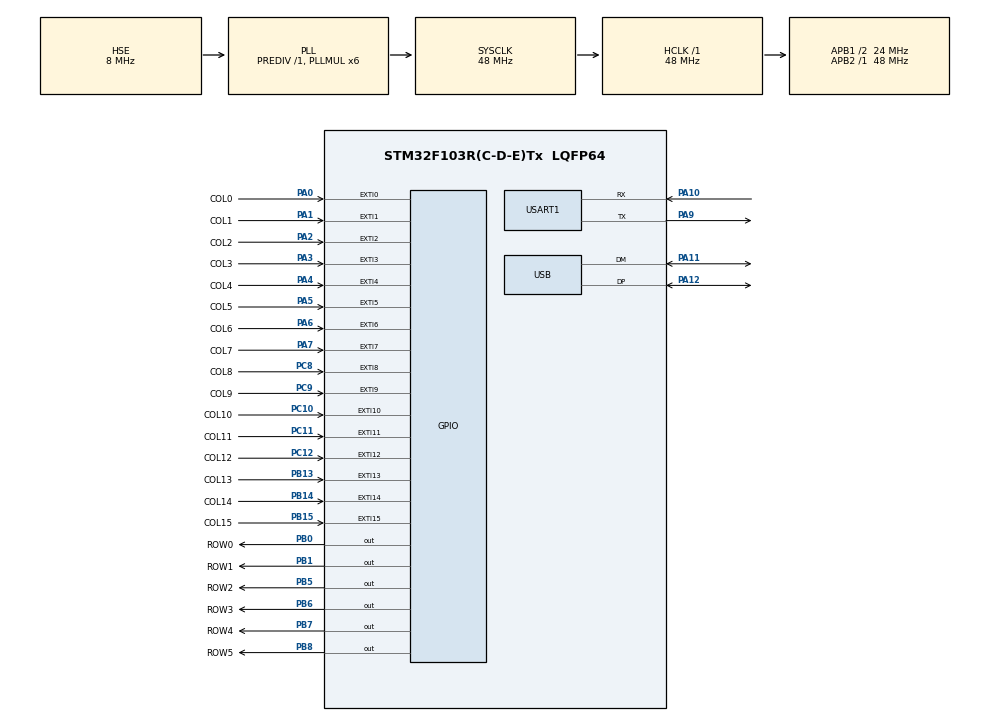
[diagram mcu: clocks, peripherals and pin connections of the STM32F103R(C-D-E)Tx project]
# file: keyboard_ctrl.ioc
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Mcu.Family=STM32F1
Mcu.Name=STM32F103R(C-D-E)Tx
Mcu.Package=LQFP64
NVIC.EXTI0_IRQn=true\:3\:0\:true\:false\:true\:true\:true\:true
NVIC.EXTI15_10_IRQn=true\:3\:0\:true\:false\:true\:true\:true\:true
NVIC.EXTI1_IRQn=true\:3\:0\:true\:false\:true\:true\:true\:true
NVIC.EXTI2_IRQn=true\:3\:0\:true\:false\:true\:true\:true\:true
NVIC.EXTI3_IRQn=true\:3\:0\:true\:false\:true\:true\:true\:true
NVIC.EXTI4_IRQn=true\:3\:0\:true\:false\:true\:true\:true\:true
NVIC.EXTI9_5_IRQn=true\:0\:0\:false\:false\:true\:true\:true\:true
NVIC.PriorityGroup=NVIC_PRIORITYGROUP_4
NVIC.TIM4_IRQn=true\:2\:0\:true\:false\:true\:true\:true\:true
NVIC.USART1_IRQn=true\:1\:0\:true\:false\:true\:true\:true\:true
NVIC.USB_LP_CAN1_RX0_IRQn=true\:0\:0\:false\:false\:true\:false\:true\:true
PA0-WKUP.GPIO_Label=COL0
PA0-WKUP.GPIO_ModeDefaultEXTI=GPIO_MODE_IT_FALLING
PA0-WKUP.GPIO_PuPd=GPIO_PULLUP
PA0-WKUP.Signal=GPXTI0
PA1.GPIO_Label=COL1
PA1.GPIO_ModeDefaultEXTI=GPIO_MODE_IT_FALLING
PA1.GPIO_PuPd=GPIO_PULLUP
PA1.Signal=GPXTI1
PA10.Mode=Asynchronous
PA10.Signal=USART1_RX
PA11.Mode=Device
PA11.Signal=USB_DM
PA12.Mode=Device
PA12.Signal=USB_DP
PA13.Mode=Serial_Wire
PA13.Signal=SYS_JTMS-SWDIO
PA14.Mode=Serial_Wire
PA14.Signal=SYS_JTCK-SWCLK
PA2.GPIO_Label=COL2
PA2.GPIO_ModeDefaultEXTI=GPIO_MODE_IT_FALLING
PA2.GPIO_PuPd=GPIO_PULLUP
PA2.Signal=GPXTI2
PA3.GPIO_Label=COL3
PA3.GPIO_ModeDefaultEXTI=GPIO_MODE_IT_FALLING
PA3.GPIO_PuPd=GPIO_PULLUP
PA3.Signal=GPXTI3
PA4.GPIO_Label=COL4
PA4.GPIO_ModeDefaultEXTI=GPIO_MODE_IT_FALLING
PA4.GPIO_PuPd=GPIO_PULLUP
PA4.Signal=GPXTI4
PA5.GPIO_Label=COL5
PA5.GPIO_ModeDefaultEXTI=GPIO_MODE_IT_FALLING
PA5.GPIO_PuPd=GPIO_PULLUP
PA5.Signal=GPXTI5
PA6.GPIO_Label=COL6
PA6.GPIO_ModeDefaultEXTI=GPIO_MODE_IT_FALLING
PA6.GPIO_PuPd=GPIO_PULLUP
PA6.Signal=GPXTI6
PA7.GPIO_Label=COL7
PA7.GPIO_ModeDefaultEXTI=GPIO_MODE_IT_FALLING
PA7.GPIO_PuPd=GPIO_PULLUP
PA7.Signal=GPXTI7
PA9.Mode=Asynchronous
PA9.Signal=USART1_TX
PB0.GPIO_Label=ROW0
PB0.GPIO_Speed=GPIO_SPEED_FREQ_HIGH
PB0.Signal=GPIO_Output
PB1.GPIO_Label=ROW1
PB1.GPIO_Speed=GPIO_SPEED_FREQ_HIGH
PB1.Signal=GPIO_Output
PB13.GPIO_Label=COL13
PB13.GPIO_ModeDefaultEXTI=GPIO_MODE_IT_FALLING
PB13.GPIO_PuPd=GPIO_PULLUP
PB13.Signal=GPXTI13
PB14.GPIO_Label=COL14
PB14.GPIO_ModeDefaultEXTI=GPIO_MODE_IT_FALLING
PB14.GPIO_PuPd=GPIO_PULLUP
PB14.Signal=GPXTI14
PB15.GPIO_Label=COL15
PB15.GPIO_ModeDefaultEXTI=GPIO_MODE_IT_FALLING
PB15.GPIO_PuPd=GPIO_PULLUP
PB15.Signal=GPXTI15
PB5.GPIO_Label=ROW2
PB5.GPIO_Speed=GPIO_SPEED_FREQ_HIGH
PB5.Signal=GPIO_Output
PB6.GPIO_Label=ROW3
PB6.GPIO_Speed=GPIO_SPEED_FREQ_HIGH
PB6.Signal=GPIO_Output
PB7.GPIO_Label=ROW4
PB7.GPIO_Speed=GPIO_SPEED_FREQ_HIGH
PB7.Signal=GPIO_Output
PB8.GPIO_Label=ROW5
PB8.GPIO_Speed=GPIO_SPEED_FREQ_HIGH
PB8.Signal=GPIO_Output
PC10.GPIO_Label=COL10
PC10.GPIO_ModeDefaultEXTI=GPIO_MODE_IT_FALLING
PC10.GPIO_PuPd=GPIO_PULLUP
PC10.Signal=GPXTI10
PC11.GPIO_Label=COL11
PC11.GPIO_ModeDefaultEXTI=GPIO_MODE_IT_FALLING
PC11.GPIO_PuPd=GPIO_PULLUP
PC11.Signal=GPXTI11
PC12.GPIO_Label=COL12
PC12.GPIO_ModeDefaultEXTI=GPIO_MODE_IT_FALLING
PC12.GPIO_PuPd=GPIO_PULLUP
PC12.Signal=GPXTI12
PC8.GPIO_Label=COL8
PC8.GPIO_ModeDefaultEXTI=GPIO_MODE_IT_FALLING
PC8.GPIO_PuPd=GPIO_PULLUP
PC8.Signal=GPXTI8
PC9.GPIO_Label=COL9
PC9.GPIO_ModeDefaultEXTI=GPIO_MODE_IT_FALLING
PC9.GPIO_PuPd=GPIO_PULLUP
PC9.Signal=GPXTI9
PD0-OSC_IN.Mode=HSE-External-Oscillator
PD0-OSC_IN.Signal=RCC_OSC_IN
PD1-OSC_OUT.Mode=HSE-External-Oscillator
PD1-OSC_OUT.Signal=RCC_OSC_OUT
ProjectManager.HeapSize=0x200
ProjectManager.StackSize=0x400
ProjectManager.TargetToolchain=CMake
RCC.AHBFreq_Value=48000000
RCC.APB1CLKDivider=RCC_HCLK_DIV2
RCC.APB1Freq_Value=24000000
RCC.APB1TimFreq_Value=48000000
RCC.APB2Freq_Value=48000000
RCC.APB2TimFreq_Value=48000000
RCC.HCLKFreq_Value=48000000
RCC.PLLMUL=RCC_PLL_MUL6
RCC.SYSCLKFreq_VALUE=48000000
RCC.SYSCLKSource=RCC_SYSCLKSOURCE_PLLCLK
RCC.USBFreq_Value=48000000
TIM4.Period=9
TIM4.Prescaler=4799
USART1.VirtualMode=VM_ASYNC
USB_DEVICE.CLASS_NAME_FS=CUSTOM_HID
USB_DEVICE.VirtualMode=CustomHid
USB_DEVICE.VirtualModeFS=Custom_Hid_FS
VP_TIM4_VS_ClockSourceINT.Mode=Internal
VP_USB_DEVICE_VS_USB_DEVICE_CUSTOM_HID_FS.Mode=CUSTOM_HID_FS
board=custom

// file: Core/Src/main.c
/* USER CODE BEGIN Header */
/**
  ******************************************************************************
  * @file           : main.c
  * @brief          : Main program body
  ******************************************************************************
  * @attention
  *
  * Copyright (c) 2026 STMicroelectronics.
  * All rights reserved.
  *
  * This software is licensed under terms that can be found in the LICENSE file
  * in the root directory of this software component.
  * If no LICENSE file comes with this software, it is provided AS-IS.
  *
  ******************************************************************************
  */
/* USER CODE END Header */
#include "main.h"
#include "tim.h"
#include "usart.h"
#include "usb_device.h"
#include "gpio.h"

/* USER CODE BEGIN Includes */
#include "keyboard.h"
#include  "uart_proto.h"
/* USER CODE END Includes */

void SystemClock_Config(void);

int main(void)
{

  /* MCU Configuration--------------------------------------------------------*/

  /* Reset of all peripherals, Initializes the Flash interface and the Systick. */
  HAL_Init();

  /* Configure the system clock */
  SystemClock_Config();

  /* Initialize all configured peripherals */
  MX_GPIO_Init();
  MX_USART1_UART_Init();
  MX_USB_DEVICE_Init();
  MX_TIM4_Init();
  UART_Manager_Init(&huart1);
  /* USER CODE BEGIN 2 */
  KeyboardInit();
  #ifdef KEYBOARD_RGB
    HAL_UARTEx_ReceiveToIdle_IT(uart_manager.uart,uart_manager.temp_buffer,100);
  #endif
  /* USER CODE END 2 */

  /* Infinite loop */
  while (1)
  {
    keyboardStart();
    #ifdef KEYBOARD_RGB
        //接受并处理命令
        if(uart_manager.RE){
          uart_manager.RE = 0;
          BufMove(uart_manager.temp_buffer,uart_manager.temp_buffer_len);
        }
        ReceiveBufferParse(Command_HandlingCallback,Position_HandlingCallback);
        //发送按键位置
        transmitPosition();
        //发送命令
        transmitCommand();
        //处理命令超时
        commandTimeoutHandler();
    #endif
  }
}

void SystemClock_Config(void)
{
  RCC_OscInitTypeDef RCC_OscInitStruct = {0};
  RCC_ClkInitTypeDef RCC_ClkInitStruct = {0};
  RCC_PeriphCLKInitTypeDef PeriphClkInit = {0};

  /** Initializes the RCC Oscillators according to the specified parameters
  * in the RCC_OscInitTypeDef structure.
  */
  RCC_OscInitStruct.OscillatorType = RCC_OSCILLATORTYPE_HSE;
  RCC_OscInitStruct.HSEState = RCC_HSE_ON;
  RCC_OscInitStruct.HSEPredivValue = RCC_HSE_PREDIV_DIV1;
  RCC_OscInitStruct.HSIState = RCC_HSI_ON;
  RCC_OscInitStruct.PLL.PLLState = RCC_PLL_ON;
  RCC_OscInitStruct.PLL.PLLSource = RCC_PLLSOURCE_HSE;
  RCC_OscInitStruct.PLL.PLLMUL = RCC_PLL_MUL6;
  if (HAL_RCC_OscConfig(&RCC_OscInitStruct) != HAL_OK)
  {
    Error_Handler();
  }

  /** Initializes the CPU, AHB and APB buses clocks
  */
  RCC_ClkInitStruct.ClockType = RCC_CLOCKTYPE_HCLK|RCC_CLOCKTYPE_SYSCLK
                              |RCC_CLOCKTYPE_PCLK1|RCC_CLOCKTYPE_PCLK2;
  RCC_ClkInitStruct.SYSCLKSource = RCC_SYSCLKSOURCE_PLLCLK;
  RCC_ClkInitStruct.AHBCLKDivider = RCC_SYSCLK_DIV1;
  RCC_ClkInitStruct.APB1CLKDivider = RCC_HCLK_DIV2;
  RCC_ClkInitStruct.APB2CLKDivider = RCC_HCLK_DIV1;

  if (HAL_RCC_ClockConfig(&RCC_ClkInitStruct, FLASH_LATENCY_1) != HAL_OK)
  {
    Error_Handler();
  }
  PeriphClkInit.PeriphClockSelection = RCC_PERIPHCLK_USB;
  PeriphClkInit.UsbClockSelection = RCC_USBCLKSOURCE_PLL;
  if (HAL_RCCEx_PeriphCLKConfig(&PeriphClkInit) != HAL_OK)
  {
    Error_Handler();
  }
}

void Error_Handler(void)
{
  __disable_irq();
  while (1)
  {
  }
}
